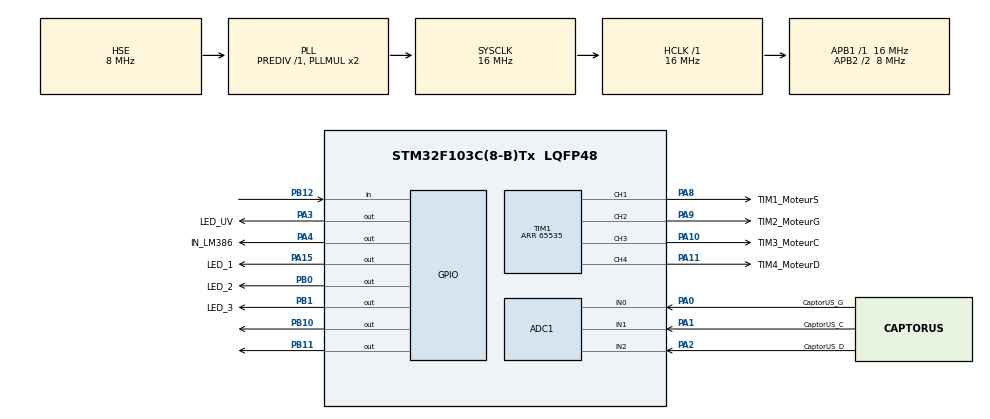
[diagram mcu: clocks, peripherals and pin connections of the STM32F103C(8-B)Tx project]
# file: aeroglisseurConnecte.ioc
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ADC1.Channel-0\#ChannelRegularConversion=ADC_CHANNEL_0
ADC1.NbrOfConversionFlag=1
ADC1.Rank-0\#ChannelRegularConversion=1
ADC1.SamplingTime-0\#ChannelRegularConversion=ADC_SAMPLETIME_1CYCLE_5
ADC1.master=1
Mcu.Family=STM32F1
Mcu.Name=STM32F103C(8-B)Tx
Mcu.Package=LQFP48
NVIC.PriorityGroup=NVIC_PRIORITYGROUP_4
PA0-WKUP.GPIO_Label=CaptorUS_G
PA0-WKUP.Signal=ADCx_IN0
PA1.GPIO_Label=CaptorUS_C
PA1.Signal=ADCx_IN1
PA10.GPIO_Label=TIM3_MoteurC
PA10.Signal=S_TIM1_CH3
PA11.GPIO_Label=TIM4_MoteurD
PA11.Signal=S_TIM1_CH4
PA15.GPIO_Label=LED_1
PA15.Signal=GPIO_Output
PA2.GPIO_Label=CaptorUS_D
PA2.Signal=ADCx_IN2
PA3.GPIO_Label=LED_UV
PA3.Signal=GPIO_Output
PA4.GPIO_Label=IN_LM386
PA4.Signal=GPIO_Output
PA5.GPIO_Label=uSD_SCK
PA5.Signal=SPI1_SCK
PA6.GPIO_Label=uSD_MISO
PA6.Signal=SPI1_MISO
PA7.GPIO_Label=uSD_MOSI
PA7.Signal=SPI1_MOSI
PA8.GPIO_Label=TIM1_MoteurS
PA8.Signal=S_TIM1_CH1
PA9.GPIO_Label=TIM2_MoteurG
PA9.Signal=S_TIM1_CH2
PB0.GPIO_Label=LED_2
PB0.Signal=GPIO_Output
PB1.GPIO_Label=LED_3
PB1.Signal=GPIO_Output
PB10.Signal=GPIO_Output
PB11.Signal=GPIO_Output
PB12.Signal=GPIO_Input
PB8.Signal=I2C1_SCL
PB9.Signal=I2C1_SDA
PD0-OSC_IN.Mode=HSE-External-Oscillator
PD0-OSC_IN.Signal=RCC_OSC_IN
PD1-OSC_OUT.Mode=HSE-External-Oscillator
PD1-OSC_OUT.Signal=RCC_OSC_OUT
ProjectManager.HeapSize=0x200
ProjectManager.StackSize=0x400
ProjectManager.TargetToolchain=SW4STM32
RCC.AHBFreq_Value=16000000
RCC.APB1Freq_Value=16000000
RCC.APB1TimFreq_Value=16000000
RCC.APB2CLKDivider=RCC_HCLK_DIV2
RCC.APB2Freq_Value=8000000
RCC.APB2TimFreq_Value=16000000
RCC.HCLKFreq_Value=16000000
RCC.PLLSourceVirtual=RCC_PLLSOURCE_HSE
RCC.SYSCLKFreq_VALUE=16000000
RCC.SYSCLKSource=RCC_SYSCLKSOURCE_PLLCLK
RCC.USBFreq_Value=16000000
SH.ADCx_IN0.0=ADC1_IN0,IN0
SH.ADCx_IN1.0=ADC1_IN1,IN1
SH.ADCx_IN2.0=ADC1_IN2,IN2
SH.S_TIM1_CH1.0=TIM1_CH1,PWM Generation1 CH1
SH.S_TIM1_CH2.0=TIM1_CH2,PWM Generation2 CH2
SH.S_TIM1_CH3.0=TIM1_CH3,PWM Generation3 CH3
SH.S_TIM1_CH4.0=TIM1_CH4,PWM Generation4 CH4
TIM1.Channel-PWM\ Generation1\ CH1=TIM_CHANNEL_1
TIM1.Channel-PWM\ Generation2\ CH2=TIM_CHANNEL_2
TIM1.Channel-PWM\ Generation3\ CH3=TIM_CHANNEL_3
TIM1.Channel-PWM\ Generation4\ CH4=TIM_CHANNEL_4
TIM1.Period=65535
TIM1.Pulse-PWM\ Generation1\ CH1=1000
TIM1.Pulse-PWM\ Generation2\ CH2=1000
TIM1.Pulse-PWM\ Generation3\ CH3=1000
TIM1.Pulse-PWM\ Generation4\ CH4=1000
VP_SYS_VS_ND.Mode=No_Debug
board=aeroglisseurConnecte

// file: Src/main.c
/**
  ******************************************************************************
  * @file           : main.c
  * @brief          : Main program body
  ******************************************************************************
  ** This notice applies to any and all portions of this file
  * that are not between comment pairs USER CODE BEGIN and
  * USER CODE END. Other portions of this file, whether
  * inserted by the user or by software development tools
  * are owned by their respective copyright owners.
  *
  * COPYRIGHT(c) 2018 STMicroelectronics
  *
  * Redistribution and use in source and binary forms, with or without modification,
  * are permitted provided that the following conditions are met:
  *   1. Redistributions of source code must retain the above copyright notice,
  *      this list of conditions and the following disclaimer.
  *   2. Redistributions in binary form must reproduce the above copyright notice,
  *      this list of conditions and the following disclaimer in the documentation
  *      and/or other materials provided with the distribution.
  *   3. Neither the name of STMicroelectronics nor the names of its contributors
  *      may be used to endorse or promote products derived from this software
  *      without specific prior written permission.
  *
  * THIS SOFTWARE IS PROVIDED BY THE COPYRIGHT HOLDERS AND CONTRIBUTORS "AS IS"
  * AND ANY EXPRESS OR IMPLIED WARRANTIES, INCLUDING, BUT NOT LIMITED TO, THE
  * IMPLIED WARRANTIES OF MERCHANTABILITY AND FITNESS FOR A PARTICULAR PURPOSE ARE
  * DISCLAIMED. IN NO EVENT SHALL THE COPYRIGHT HOLDER OR CONTRIBUTORS BE LIABLE
  * FOR ANY DIRECT, INDIRECT, INCIDENTAL, SPECIAL, EXEMPLARY, OR CONSEQUENTIAL
  * DAMAGES (INCLUDING, BUT NOT LIMITED TO, PROCUREMENT OF SUBSTITUTE GOODS OR
  * SERVICES; LOSS OF USE, DATA, OR PROFITS; OR BUSINESS INTERRUPTION) HOWEVER
  * CAUSED AND ON ANY THEORY OF LIABILITY, WHETHER IN CONTRACT, STRICT LIABILITY,
  * OR TORT (INCLUDING NEGLIGENCE OR OTHERWISE) ARISING IN ANY WAY OUT OF THE USE
  * OF THIS SOFTWARE, EVEN IF ADVISED OF THE POSSIBILITY OF SUCH DAMAGE.
  *
  ******************************************************************************
  */
#include "main.h"
#include "stm32f1xx_hal.h"

ADC_HandleTypeDef hadc1;

TIM_HandleTypeDef htim1;

/* USER CODE BEGIN PV */
/* Private variables ---------------------------------------------------------*/

/* USER CODE END PV */

void SystemClock_Config(void);
static void MX_GPIO_Init(void);
static void MX_ADC1_Init(void);
static void MX_TIM1_Init(void);

void HAL_TIM_MspPostInit(TIM_HandleTypeDef *htim);

/* USER CODE BEGIN PFP */
/* Private function prototypes -----------------------------------------------*/

/* USER CODE END PFP */

int main(void)
{

  /* MCU Configuration----------------------------------------------------------*/

  /* Reset of all peripherals, Initializes the Flash interface and the Systick. */
  HAL_Init();

  /* Configure the system clock */
  SystemClock_Config();

  /* Initialize all configured peripherals */
  MX_GPIO_Init();
  MX_ADC1_Init();
  MX_TIM1_Init();
  /* USER CODE BEGIN 2 */

  HAL_TIM_Base_Start_IT(&htim1);
  HAL_TIM_PWM_Start(&htim1,TIM_CHANNEL_1);
  HAL_TIM_PWM_Start(&htim1,TIM_CHANNEL_2);
  HAL_TIM_PWM_Start(&htim1,TIM_CHANNEL_3);
  HAL_TIM_PWM_Start(&htim1,TIM_CHANNEL_4);

  /* USER CODE END 2 */

  /* Infinite loop */
  while (1)
  {

  /* USER CODE BEGIN 3 */

	  // LED 1 clignote
	  HAL_GPIO_TogglePin(GPIOA, LED_1_Pin);
	  HAL_Delay(500);

  }
  /* USER CODE END 3 */

}

void SystemClock_Config(void)
{

  RCC_OscInitTypeDef RCC_OscInitStruct;
  RCC_ClkInitTypeDef RCC_ClkInitStruct;
  RCC_PeriphCLKInitTypeDef PeriphClkInit;

    /**Initializes the CPU, AHB and APB busses clocks
    */
  RCC_OscInitStruct.OscillatorType = RCC_OSCILLATORTYPE_HSE;
  RCC_OscInitStruct.HSEState = RCC_HSE_ON;
  RCC_OscInitStruct.HSEPredivValue = RCC_HSE_PREDIV_DIV1;
  RCC_OscInitStruct.HSIState = RCC_HSI_ON;
  RCC_OscInitStruct.PLL.PLLState = RCC_PLL_ON;
  RCC_OscInitStruct.PLL.PLLSource = RCC_PLLSOURCE_HSE;
  RCC_OscInitStruct.PLL.PLLMUL = RCC_PLL_MUL2;
  if (HAL_RCC_OscConfig(&RCC_OscInitStruct) != HAL_OK)
  {
    _Error_Handler(__FILE__, __LINE__);
  }

    /**Initializes the CPU, AHB and APB busses clocks
    */
  RCC_ClkInitStruct.ClockType = RCC_CLOCKTYPE_HCLK|RCC_CLOCKTYPE_SYSCLK
                              |RCC_CLOCKTYPE_PCLK1|RCC_CLOCKTYPE_PCLK2;
  RCC_ClkInitStruct.SYSCLKSource = RCC_SYSCLKSOURCE_PLLCLK;
  RCC_ClkInitStruct.AHBCLKDivider = RCC_SYSCLK_DIV1;
  RCC_ClkInitStruct.APB1CLKDivider = RCC_HCLK_DIV1;
  RCC_ClkInitStruct.APB2CLKDivider = RCC_HCLK_DIV2;

  if (HAL_RCC_ClockConfig(&RCC_ClkInitStruct, FLASH_LATENCY_0) != HAL_OK)
  {
    _Error_Handler(__FILE__, __LINE__);
  }

  PeriphClkInit.PeriphClockSelection = RCC_PERIPHCLK_ADC;
  PeriphClkInit.AdcClockSelection = RCC_ADCPCLK2_DIV2;
  if (HAL_RCCEx_PeriphCLKConfig(&PeriphClkInit) != HAL_OK)
  {
    _Error_Handler(__FILE__, __LINE__);
  }

    /**Configure the Systick interrupt time
    */
  HAL_SYSTICK_Config(HAL_RCC_GetHCLKFreq()/1000);

    /**Configure the Systick
    */
  HAL_SYSTICK_CLKSourceConfig(SYSTICK_CLKSOURCE_HCLK);

  /* SysTick_IRQn interrupt configuration */
  HAL_NVIC_SetPriority(SysTick_IRQn, 0, 0);
}

/* ADC1 init function */
static void MX_ADC1_Init(void)
{

  ADC_ChannelConfTypeDef sConfig;

    /**Common config
    */
  hadc1.Instance = ADC1;
  hadc1.Init.ScanConvMode = ADC_SCAN_DISABLE;
  hadc1.Init.ContinuousConvMode = DISABLE;
  hadc1.Init.DiscontinuousConvMode = DISABLE;
  hadc1.Init.ExternalTrigConv = ADC_SOFTWARE_START;
  hadc1.Init.DataAlign = ADC_DATAALIGN_RIGHT;
  hadc1.Init.NbrOfConversion = 1;
  if (HAL_ADC_Init(&hadc1) != HAL_OK)
  {
    _Error_Handler(__FILE__, __LINE__);
  }

    /**Configure Regular Channel
    */
  sConfig.Channel = ADC_CHANNEL_0;
  sConfig.Rank = ADC_REGULAR_RANK_1;
  sConfig.SamplingTime = ADC_SAMPLETIME_1CYCLE_5;
  if (HAL_ADC_ConfigChannel(&hadc1, &sConfig) != HAL_OK)
  {
    _Error_Handler(__FILE__, __LINE__);
  }

}

/* TIM1 init function */
static void MX_TIM1_Init(void)
{

  TIM_MasterConfigTypeDef sMasterConfig;
  TIM_OC_InitTypeDef sConfigOC;
  TIM_BreakDeadTimeConfigTypeDef sBreakDeadTimeConfig;

  htim1.Instance = TIM1;
  htim1.Init.Prescaler = 0;
  htim1.Init.CounterMode = TIM_COUNTERMODE_UP;
  htim1.Init.Period = 65535;
  htim1.Init.ClockDivision = TIM_CLOCKDIVISION_DIV1;
  htim1.Init.RepetitionCounter = 0;
  htim1.Init.AutoReloadPreload = TIM_AUTORELOAD_PRELOAD_DISABLE;
  if (HAL_TIM_PWM_Init(&htim1) != HAL_OK)
  {
    _Error_Handler(__FILE__, __LINE__);
  }

  sMasterConfig.MasterOutputTrigger = TIM_TRGO_RESET;
  sMasterConfig.MasterSlaveMode = TIM_MASTERSLAVEMODE_DISABLE;
  if (HAL_TIMEx_MasterConfigSynchronization(&htim1, &sMasterConfig) != HAL_OK)
  {
    _Error_Handler(__FILE__, __LINE__);
  }

  sConfigOC.OCMode = TIM_OCMODE_PWM1;
  sConfigOC.Pulse = 10000; // à diviser par 65535
  sConfigOC.OCPolarity = TIM_OCPOLARITY_HIGH;
  sConfigOC.OCNPolarity = TIM_OCNPOLARITY_HIGH;
  sConfigOC.OCFastMode = TIM_OCFAST_DISABLE;
  sConfigOC.OCIdleState = TIM_OCIDLESTATE_RESET;
  sConfigOC.OCNIdleState = TIM_OCNIDLESTATE_RESET;
  if (HAL_TIM_PWM_ConfigChannel(&htim1, &sConfigOC, TIM_CHANNEL_1) != HAL_OK)
  {
    _Error_Handler(__FILE__, __LINE__);
  }
  sConfigOC.Pulse = 30000; // à diviser par 65535

  if (HAL_TIM_PWM_ConfigChannel(&htim1, &sConfigOC, TIM_CHANNEL_2) != HAL_OK)
  {
    _Error_Handler(__FILE__, __LINE__);
  }
  sConfigOC.Pulse = 45000; // à diviser par 65535

  if (HAL_TIM_PWM_ConfigChannel(&htim1, &sConfigOC, TIM_CHANNEL_3) != HAL_OK)
  {
    _Error_Handler(__FILE__, __LINE__);
  }
  sConfigOC.Pulse = 60000; // à diviser par 65535

  if (HAL_TIM_PWM_ConfigChannel(&htim1, &sConfigOC, TIM_CHANNEL_4) != HAL_OK)
  {
    _Error_Handler(__FILE__, __LINE__);
  }

  sBreakDeadTimeConfig.OffStateRunMode = TIM_OSSR_DISABLE;
  sBreakDeadTimeConfig.OffStateIDLEMode = TIM_OSSI_DISABLE;
  sBreakDeadTimeConfig.LockLevel = TIM_LOCKLEVEL_OFF;
  sBreakDeadTimeConfig.DeadTime = 0;
  sBreakDeadTimeConfig.BreakState = TIM_BREAK_DISABLE;
  sBreakDeadTimeConfig.BreakPolarity = TIM_BREAKPOLARITY_HIGH;
  sBreakDeadTimeConfig.AutomaticOutput = TIM_AUTOMATICOUTPUT_DISABLE;
  if (HAL_TIMEx_ConfigBreakDeadTime(&htim1, &sBreakDeadTimeConfig) != HAL_OK)
  {
    _Error_Handler(__FILE__, __LINE__);
  }

  HAL_TIM_MspPostInit(&htim1);

}

/** Configure pins as
        * Analog
        * Input
        * Output
        * EVENT_OUT
        * EXTI
     PA5   ------> SPI1_SCK
     PA6   ------> SPI1_MISO
     PA7   ------> SPI1_MOSI
     PB8   ------> I2C1_SCL
     PB9   ------> I2C1_SDA
*/
static void MX_GPIO_Init(void)
{

  GPIO_InitTypeDef GPIO_InitStruct;

  /* GPIO Ports Clock Enable */
  __HAL_RCC_GPIOD_CLK_ENABLE();
  __HAL_RCC_GPIOA_CLK_ENABLE();
  __HAL_RCC_GPIOB_CLK_ENABLE();

  /*Configure GPIO pin Output Level */
  HAL_GPIO_WritePin(GPIOA, LED_UV_Pin|IN_LM386_Pin|LED_1_Pin, GPIO_PIN_RESET);

  /*Configure GPIO pin Output Level */
  HAL_GPIO_WritePin(GPIOB, LED_2_Pin|LED_3_Pin|GPIO_PIN_10|GPIO_PIN_11, GPIO_PIN_RESET);

  /*Configure GPIO pins : LED_UV_Pin IN_LM386_Pin LED_1_Pin */
  GPIO_InitStruct.Pin = LED_UV_Pin|IN_LM386_Pin|LED_1_Pin;
  GPIO_InitStruct.Mode = GPIO_MODE_OUTPUT_PP;
  GPIO_InitStruct.Speed = GPIO_SPEED_FREQ_LOW;
  HAL_GPIO_Init(GPIOA, &GPIO_InitStruct);

  /*Configure GPIO pins : uSD_SCK_Pin uSD_MISO_Pin uSD_MOSI_Pin */
  GPIO_InitStruct.Pin = uSD_SCK_Pin|uSD_MISO_Pin|uSD_MOSI_Pin;
  GPIO_InitStruct.Mode = GPIO_MODE_AF_PP;
  GPIO_InitStruct.Speed = GPIO_SPEED_FREQ_HIGH;
  HAL_GPIO_Init(GPIOA, &GPIO_InitStruct);

  /*Configure GPIO pins : LED_2_Pin LED_3_Pin PB10 PB11 */
  GPIO_InitStruct.Pin = LED_2_Pin|LED_3_Pin|GPIO_PIN_10|GPIO_PIN_11;
  GPIO_InitStruct.Mode = GPIO_MODE_OUTPUT_PP;
  GPIO_InitStruct.Speed = GPIO_SPEED_FREQ_LOW;
  HAL_GPIO_Init(GPIOB, &GPIO_InitStruct);

  /*Configure GPIO pin : PB12 */
  GPIO_InitStruct.Pin = GPIO_PIN_12;
  GPIO_InitStruct.Mode = GPIO_MODE_INPUT;
  GPIO_InitStruct.Pull = GPIO_NOPULL;
  HAL_GPIO_Init(GPIOB, &GPIO_InitStruct);

  /*Configure GPIO pins : PB8 PB9 */
  GPIO_InitStruct.Pin = GPIO_PIN_8|GPIO_PIN_9;
  GPIO_InitStruct.Mode = GPIO_MODE_AF_OD;
  GPIO_InitStruct.Speed = GPIO_SPEED_FREQ_HIGH;
  HAL_GPIO_Init(GPIOB, &GPIO_InitStruct);

  /*Configure peripheral I/O remapping */
  __HAL_AFIO_REMAP_I2C1_ENABLE();

}

void _Error_Handler(char *file, int line)
{
  while(1)
  {
  }
}

/************************ (C) COPYRIGHT STMicroelectronics *****END OF FILE****/
